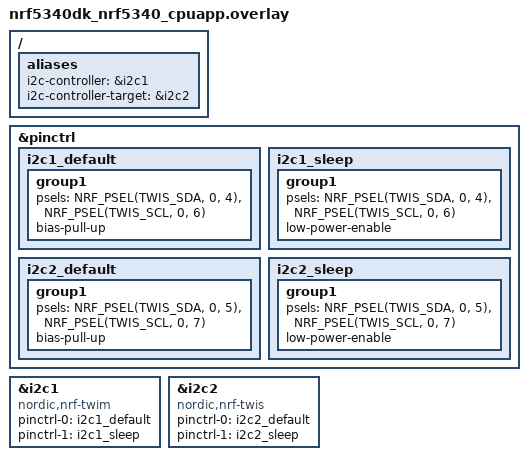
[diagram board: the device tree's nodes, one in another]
/*
 * Copyright (c) 2024 Nordic Semiconductor ASA
 *
 * SPDX-License-Identifier: Apache-2.0
 */

/ {
	aliases {
		i2c-controller = &i2c1;
		i2c-controller-target = &i2c2;
	};
};

&pinctrl {
	i2c1_default: i2c1_default {
		group1 {
			psels = <NRF_PSEL(TWIS_SDA, 0, 4)>,
				<NRF_PSEL(TWIS_SCL, 0, 6)>;
			bias-pull-up;
		};
	};

	i2c1_sleep: i2c1_sleep {
		group1 {
			psels = <NRF_PSEL(TWIS_SDA, 0, 4)>,
				<NRF_PSEL(TWIS_SCL, 0, 6)>;
			low-power-enable;
		};
	};

	i2c2_default: i2c2_default {
		group1 {
			psels = <NRF_PSEL(TWIS_SDA, 0, 5)>,
				<NRF_PSEL(TWIS_SCL, 0, 7)>;
			bias-pull-up;
		};
	};

	i2c2_sleep: i2c2_sleep {
		group1 {
			psels = <NRF_PSEL(TWIS_SDA, 0, 5)>,
				<NRF_PSEL(TWIS_SCL, 0, 7)>;
			low-power-enable;
		};
	};
};

&i2c1 {
	compatible = "nordic,nrf-twim";
	pinctrl-0 = <&i2c1_default>;
	pinctrl-1 = <&i2c1_sleep>;
	pinctrl-names = "default", "sleep";
	status = "okay";
};

&i2c2 {
	compatible = "nordic,nrf-twis";
	pinctrl-0 = <&i2c2_default>;
	pinctrl-1 = <&i2c2_sleep>;
	pinctrl-names = "default", "sleep";
	status = "okay";
};
